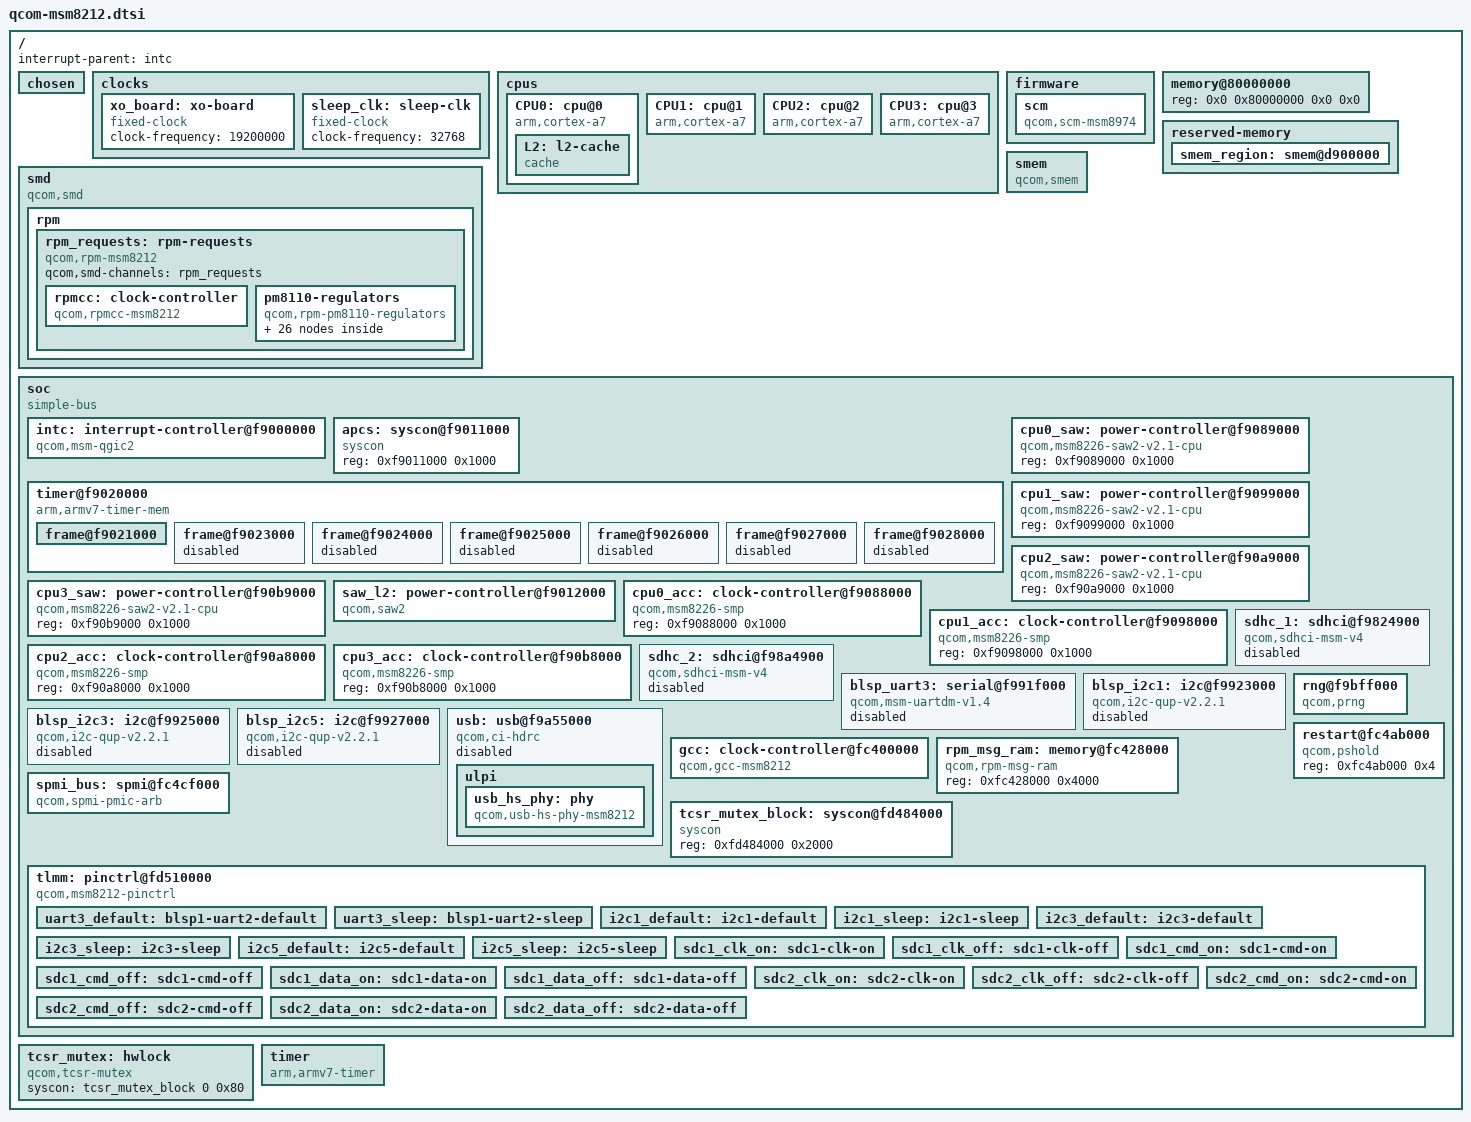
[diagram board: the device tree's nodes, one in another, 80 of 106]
// SPDX-License-Identifier: BSD-3-Clause
/*
 * Copyright (c) 2021, Konrad Dybcio
 * Copyright (c) 2021, Ivaylo Ivanov <ivo.ivanov@null.net>
 */

#include <dt-bindings/clock/qcom,gcc-msm8974.h>
#include <dt-bindings/clock/qcom,rpmcc.h>
#include <dt-bindings/gpio/gpio.h>
#include <dt-bindings/interrupt-controller/arm-gic.h>
#include <dt-bindings/reset/qcom,gcc-msm8974.h>

/ {
	interrupt-parent = <&intc>;

	#address-cells = <2>;
	#size-cells = <2>;

	chosen { };

	clocks {
		xo_board: xo-board {
			compatible = "fixed-clock";
			#clock-cells = <0>;
			clock-frequency = <19200000>;
		};

		sleep_clk: sleep-clk {
			compatible = "fixed-clock";
			#clock-cells = <0>;
			clock-frequency = <32768>;
		};
	};

	cpus {
		#address-cells = <1>;
		#size-cells = <0>;

		CPU0: cpu@0 {
			compatible = "arm,cortex-a7";
			enable-method = "qcom,msm8226-smp";
			device_type = "cpu";
			reg = <0>;
			next-level-cache = <&L2>;
			qcom,acc = <&cpu0_acc>;
			qcom,saw = <&cpu0_saw>;

			L2: l2-cache {
				compatible = "cache";
				cache-level = <2>;
				qcom,saw = <&saw_l2>;
			};
		};

		CPU1: cpu@1 {
			compatible = "arm,cortex-a7";
			enable-method = "qcom,msm8226-smp";
			device_type = "cpu";
			reg = <1>;
			next-level-cache = <&L2>;
			qcom,acc = <&cpu1_acc>;
			qcom,saw = <&cpu1_saw>;
		};

		CPU2: cpu@2 {
			compatible = "arm,cortex-a7";
			enable-method = "qcom,msm8226-smp";
			device_type = "cpu";
			reg = <2>;
			next-level-cache = <&L2>;
			qcom,acc = <&cpu2_acc>;
			qcom,saw = <&cpu2_saw>;
		};

		CPU3: cpu@3 {
			compatible = "arm,cortex-a7";
			enable-method = "qcom,msm8226-smp";
			device_type = "cpu";
			reg = <3>;
			next-level-cache = <&L2>;
			qcom,acc = <&cpu3_acc>;
			qcom,saw = <&cpu3_saw>;
		};
	};

	firmware {
		scm {
			compatible = "qcom,scm-msm8974", "qcom,scm";
			clocks = <&gcc GCC_CE1_CLK>,
				 <&gcc GCC_CE1_AXI_CLK>,
				 <&gcc GCC_CE1_AHB_CLK>;
			clock-names = "core", "bus", "iface";
		};
	};

	memory@80000000 {
		device_type = "memory";
		/* We expect the bootloader to fill in the reg */
		reg = <0x0 0x80000000 0x0 0x0>;
	};

	reserved-memory {
		#address-cells = <2>;
		#size-cells = <2>;
		ranges;

		smem_region: smem@d900000 {
			reg = <0 0xd900000 0 0x100000>;
			no-map;
		};
	};

	smd {
		compatible = "qcom,smd";

		rpm {
			interrupts = <GIC_SPI 168 IRQ_TYPE_EDGE_RISING>;
			qcom,ipc = <&apcs 8 0>;
			qcom,smd-edge = <15>;

			rpm_requests: rpm-requests {
				compatible = "qcom,rpm-msm8212";
				qcom,smd-channels = "rpm_requests";

				rpmcc: clock-controller {
					compatible = "qcom,rpmcc-msm8212", "qcom,rpmcc";
					#clock-cells = <1>;
				};

				pm8110-regulators {
					compatible = "qcom,rpm-pm8110-regulators";

					pm8110_s1: s1 {};
					pm8110_s2: s2 {};
					pm8110_s3: s3 {};
					pm8110_s4: s4 {};

					pm8110_l1: l1 {};
					pm8110_l2: l2 {};
					pm8110_l3: l3 {};
					pm8110_l4: l4 {};
					pm8110_l5: l5 {};
					pm8110_l6: l6 {};
					pm8110_l7: l7 {};
					pm8110_l8: l8 {};
					pm8110_l9: l9 {};
					pm8110_l10: l10 {};
					pm8110_l11: l11 {};
					pm8110_l12: l12 {};
					pm8110_l13: l13 {};
					pm8110_l14: l14 {};
					pm8110_l15: l15 {};
					pm8110_l16: l16 {};
					pm8110_l17: l17 {};
					pm8110_l18: l18 {};
					pm8110_l19: l19 {};
					pm8110_l20: l20 {};
					pm8110_l21: l21 {};
					pm8110_l22: l22 {};
				};
			};
		};
	};

	smem {
		compatible = "qcom,smem";

		memory-region = <&smem_region>;
		qcom,rpm-msg-ram = <&rpm_msg_ram>;

		hwlocks = <&tcsr_mutex 3>;
	};

	soc: soc {
		#address-cells = <1>;
		#size-cells = <1>;
		ranges = <0 0 0 0xffffffff>;
		compatible = "simple-bus";

		intc: interrupt-controller@f9000000 {
			compatible = "qcom,msm-qgic2";
			reg = <0xf9000000 0x1000>,
			      <0xf9002000 0x1000>;
			interrupt-controller;
			#interrupt-cells = <3>;
		};

		apcs: syscon@f9011000 {
			compatible = "syscon";
			reg = <0xf9011000 0x1000>;
		};

		timer@f9020000 {
			compatible = "arm,armv7-timer-mem";
			reg = <0xf9020000 0x1000>;
			clock-frequency = <19200000>;
			#address-cells = <1>;
			#size-cells = <1>;
			ranges;

			frame@f9021000 {
				frame-number = <0>;
				interrupts = <GIC_SPI 8 IRQ_TYPE_LEVEL_HIGH>,
					     <GIC_SPI 7 IRQ_TYPE_LEVEL_HIGH>;
				reg = <0xf9021000 0x1000>,
				      <0xf9022000 0x1000>;
			};

			frame@f9023000 {
				frame-number = <1>;
				interrupts = <GIC_SPI 9 IRQ_TYPE_LEVEL_HIGH>;
				reg = <0xf9023000 0x1000>;
				status = "disabled";
			};

			frame@f9024000 {
				frame-number = <2>;
				interrupts = <GIC_SPI 10 IRQ_TYPE_LEVEL_HIGH>;
				reg = <0xf9024000 0x1000>;
				status = "disabled";
			};

			frame@f9025000 {
				frame-number = <3>;
				interrupts = <GIC_SPI 11 IRQ_TYPE_LEVEL_HIGH>;
				reg = <0xf9025000 0x1000>;
				status = "disabled";
			};

			frame@f9026000 {
				frame-number = <4>;
				interrupts = <GIC_SPI 12 IRQ_TYPE_LEVEL_HIGH>;
				reg = <0xf9026000 0x1000>;
				status = "disabled";
			};

			frame@f9027000 {
				frame-number = <5>;
				interrupts = <GIC_SPI 13 IRQ_TYPE_LEVEL_HIGH>;
				reg = <0xf9027000 0x1000>;
				status = "disabled";
			};

			frame@f9028000 {
				frame-number = <6>;
				interrupts = <GIC_SPI 14 IRQ_TYPE_LEVEL_HIGH>;
				reg = <0xf9028000 0x1000>;
				status = "disabled";
			};
		};

		cpu0_saw: power-controller@f9089000 {
			compatible = "qcom,msm8226-saw2-v2.1-cpu", "qcom,saw2";
			reg = <0xf9089000 0x1000>;
		};

		cpu1_saw: power-controller@f9099000 {
			compatible = "qcom,msm8226-saw2-v2.1-cpu", "qcom,saw2";
			reg = <0xf9099000 0x1000>;
		};

		cpu2_saw: power-controller@f90a9000 {
			compatible = "qcom,msm8226-saw2-v2.1-cpu", "qcom,saw2";
			reg = <0xf90a9000 0x1000>;
		};

		cpu3_saw: power-controller@f90b9000 {
			compatible = "qcom,msm8226-saw2-v2.1-cpu", "qcom,saw2";
			reg = <0xf90b9000 0x1000>;
		};

		saw_l2: power-controller@f9012000 {
			compatible = "qcom,saw2";
			reg = <0xf9012000 0x1000>;
			regulator;
		};

		cpu0_acc: clock-controller@f9088000 {
			compatible = "qcom,msm8226-smp";
			reg = <0xf9088000 0x1000>;
		};

		cpu1_acc: clock-controller@f9098000 {
			compatible = "qcom,msm8226-smp";
			reg = <0xf9098000 0x1000>;
		};

		cpu2_acc: clock-controller@f90a8000 {
			compatible = "qcom,msm8226-smp";
			reg = <0xf90a8000 0x1000>;
		};

		cpu3_acc: clock-controller@f90b8000 {
			compatible = "qcom,msm8226-smp";
			reg = <0xf90b8000 0x1000>;
		};

		sdhc_1: sdhci@f9824900 {
			compatible = "qcom,sdhci-msm-v4";
			reg = <0xf9824900 0x11c>, <0xf9824000 0x800>;
			reg-names = "hc_mem", "core_mem";

			interrupts = <GIC_SPI 123 IRQ_TYPE_LEVEL_HIGH>,
				     <GIC_SPI 138 IRQ_TYPE_LEVEL_HIGH>;
			interrupt-names = "hc_irq", "pwr_irq";

			clocks = <&gcc GCC_SDCC1_APPS_CLK>,
				 <&gcc GCC_SDCC1_AHB_CLK>,
				 <&xo_board>;
			clock-names = "core", "iface", "xo";

			pinctrl-names = "default", "sleep";
			pinctrl-0 = <&sdc1_clk_on &sdc1_cmd_on &sdc1_data_on>;
			pinctrl-1 = <&sdc1_clk_off &sdc1_cmd_off &sdc1_data_off>;

			bus-width = <8>;
			non-removable;

			status = "disabled";
		};

		sdhc_2: sdhci@f98a4900 {
			compatible = "qcom,sdhci-msm-v4";
			reg = <0xf98a4900 0x11c>, <0xf98a4000 0x800>;
			reg-names = "hc_mem", "core_mem";

			interrupts = <GIC_SPI 125 IRQ_TYPE_LEVEL_HIGH>,
				     <GIC_SPI 221 IRQ_TYPE_LEVEL_HIGH>;
			interrupt-names = "hc_irq", "pwr_irq";

			clocks = <&gcc GCC_SDCC2_APPS_CLK>,
				 <&gcc GCC_SDCC2_AHB_CLK>,
				 <&xo_board>;
			clock-names = "core", "iface", "xo";

			pinctrl-names = "default", "sleep";
			pinctrl-0 = <&sdc2_clk_on &sdc2_cmd_on &sdc2_data_on>;
			pinctrl-1 = <&sdc2_clk_off &sdc2_cmd_off &sdc2_data_off>;

			bus-width = <8>;
			non-removable;

			status = "disabled";
		};

		blsp_uart3: serial@f991f000 {
			compatible = "qcom,msm-uartdm-v1.4", "qcom,msm-uartdm";
			reg = <0xf991f000 0x1000>;
			interrupts = <GIC_SPI 109 IRQ_TYPE_LEVEL_HIGH>;
			clock-names = "core", "iface";
			clocks = <&gcc GCC_BLSP1_UART3_APPS_CLK>,
				 <&gcc GCC_BLSP1_AHB_CLK>;
			pinctrl-names = "default", "sleep";
			pinctrl-0 = <&uart3_default>;
			pinctrl-1 = <&uart3_sleep>;
			status = "disabled";
		};

		blsp_i2c1: i2c@f9923000 {	
			compatible = "qcom,i2c-qup-v2.2.1";
			reg = <0xf9923000 0x1000>;
			interrupts = <GIC_SPI 95 IRQ_TYPE_LEVEL_HIGH>;

			clocks = <&gcc GCC_BLSP1_QUP1_I2C_APPS_CLK>,
				 <&gcc GCC_BLSP1_AHB_CLK>;
			clock-names = "core", "iface";
			clock-frequency = <400000>;

			pinctrl-names = "default", "sleep";
			pinctrl-0 = <&i2c1_default>;
			pinctrl-1 = <&i2c1_sleep>;
			#address-cells = <1>;
			#size-cells = <0>;
			status = "disabled";
		};

		/* I2C2 doesn't exist */

		blsp_i2c3: i2c@f9925000 {
			compatible = "qcom,i2c-qup-v2.2.1";
			reg = <0xf9925000 0x1000>;
			interrupts = <GIC_SPI 97 IRQ_TYPE_LEVEL_HIGH>;

			clocks = <&gcc GCC_BLSP1_QUP3_I2C_APPS_CLK>,
				 <&gcc GCC_BLSP1_AHB_CLK>;
			clock-names = "core", "iface";
			clock-frequency = <400000>;

			pinctrl-names = "default", "sleep";
			pinctrl-0 = <&i2c3_default>;
			pinctrl-1 = <&i2c3_sleep>;
			#address-cells = <1>;
			#size-cells = <0>;
			status = "disabled";
		};

		/* I2C4 doesn't exist */

		blsp_i2c5: i2c@f9927000 {
			compatible = "qcom,i2c-qup-v2.2.1";
			reg = <0xf9927000 0x1000>;
			interrupts = <GIC_SPI 101 IRQ_TYPE_LEVEL_HIGH>;

			clocks = <&gcc GCC_BLSP1_QUP5_I2C_APPS_CLK>,
				 <&gcc GCC_BLSP1_AHB_CLK>;
			clock-names = "core", "iface";
			clock-frequency = <400000>;

			pinctrl-names = "default", "sleep";
			pinctrl-0 = <&i2c5_default>;
			pinctrl-1 = <&i2c5_sleep>;
			#address-cells = <1>;
			#size-cells = <0>;
			status = "disabled";
		};

		usb: usb@f9a55000 {
			compatible = "qcom,ci-hdrc";
			reg = <0xf9a55000 0x200>,
			      <0xf9a55200 0x200>;
			interrupts = <GIC_SPI 134 IRQ_TYPE_LEVEL_HIGH>;
			clocks = <&gcc GCC_USB_HS_AHB_CLK>,
				 <&gcc GCC_USB_HS_SYSTEM_CLK>;
			clock-names = "iface", "core";
			assigned-clocks = <&gcc GCC_USB_HS_SYSTEM_CLK>;
			assigned-clock-rates = <75000000>;
			resets = <&gcc GCC_USB_HS_BCR>;
			reset-names = "core";
			phy_type = "ulpi";
			dr_mode = "otg";
			hnp-disable;
			srp-disable;
			adp-disable;
			ahb-burst-config = <0>;
			phy-names = "usb-phy";
			phys = <&usb_hs_phy>;
			status = "disabled";
			#reset-cells = <1>;

			ulpi {
				usb_hs_phy: phy {
					compatible = "qcom,usb-hs-phy-msm8212",
							"qcom,usb-hs-phy";
					#phy-cells = <0>;
					clocks = <&xo_board>,
						 <&gcc GCC_USB2A_PHY_SLEEP_CLK>;
					clock-names = "ref", "sleep";
					resets = <&gcc GCC_USB2A_PHY_BCR>,
						 <&usb 0>;
					reset-names = "phy", "por";
					qcom,init-seq = /bits/ 8 <0x0 0x44
						0x1 0x68 0x2 0x24 0x3 0x13>;
				};
			};
		};

		rng@f9bff000 {
			compatible = "qcom,prng";
			reg = <0xf9bff000 0x200>;
			clocks = <&gcc GCC_PRNG_AHB_CLK>;
			clock-names = "core";
		};

		gcc: clock-controller@fc400000 {
			compatible = "qcom,gcc-msm8212";
			#clock-cells = <1>;
			#reset-cells = <1>;
			#power-domain-cells = <1>;
			reg = <0xfc400000 0x2000>;

			clock-names = "xo", "sleep_clk";
			clocks = <&xo_board>,
				 <&sleep_clk>;
		};

		rpm_msg_ram: memory@fc428000 {
			compatible = "qcom,rpm-msg-ram";
			reg = <0xfc428000 0x4000>;
		};


		restart@fc4ab000 {
			compatible = "qcom,pshold";
			reg = <0xfc4ab000 0x4>;
		};

		spmi_bus: spmi@fc4cf000 {
			compatible = "qcom,spmi-pmic-arb";
			reg-names = "core", "intr", "cnfg";
			reg = <0xfc4cf000 0x1000>,
			      <0xfc4cb000 0x1000>,
			      <0xfc4ca000 0x1000>;
			interrupt-names = "periph_irq";
			interrupts = <GIC_SPI 190 IRQ_TYPE_LEVEL_HIGH>;
			qcom,ee = <0>;
			qcom,channel = <0>;
			#address-cells = <2>;
			#size-cells = <0>;
			interrupt-controller;
			#interrupt-cells = <4>;
		};

		tcsr_mutex_block: syscon@fd484000 {
			compatible = "syscon";
			reg = <0xfd484000 0x2000>;
		};

		tlmm: pinctrl@fd510000 {
			compatible = "qcom,msm8212-pinctrl";
			reg = <0xfd510000 0x4000>;
			interrupts = <GIC_SPI 208 IRQ_TYPE_LEVEL_HIGH>;
			gpio-controller;
			gpio-ranges = <&tlmm 0 0 102>;
			#gpio-cells = <2>;
			interrupt-controller;
			#interrupt-cells = <2>;

			uart3_default: blsp1-uart2-default {
				function = "blsp_uart3";
				pins = "gpio8", "gpio9";
				drive-strength = <16>;
				bias-disable;
			};

			uart3_sleep: blsp1-uart2-sleep {
				function = "gpio";
				pins = "gpio8", "gpio9";
				drive-strength = <2>;
				bias-pull-down;
			};

			i2c1_default: i2c1-default {
				pins = "gpio2", "gpio3";
				function = "blsp_i2c1";
				drive-strength = <2>;
				bias-disable;
			};

			i2c1_sleep: i2c1-sleep {
				pins = "gpio2", "gpio3";
				function = "blsp_i2c1";
				drive-strength = <2>;
				bias-pull-up;
			};

			i2c3_default: i2c3-default {
				pins = "gpio10", "gpio11";
				function = "blsp_i2c3";
				drive-strength = <2>;
				bias-disable;
			};

			i2c3_sleep: i2c3-sleep {
				pins = "gpio10", "gpio11";
				function = "blsp_i2c3";
				drive-strength = <2>;
				bias-pull-up;
			};

			i2c5_default: i2c5-default {
				pins = "gpio18", "gpio19";
				function = "blsp_i2c5";
				drive-strength = <2>;
				bias-disable;
			};

			i2c5_sleep: i2c5-sleep {
				pins = "gpio18", "gpio19";
				function = "blsp_i2c5";
				drive-strength = <2>;
				bias-pull-up;
			};

			sdc1_clk_on: sdc1-clk-on {
				pins = "sdc1_clk";
				bias-disable;
				drive-strength = <16>;
			};

			sdc1_clk_off: sdc1-clk-off {
				pins = "sdc1_clk";
				bias-disable;
				drive-strength = <2>;
			};

			sdc1_cmd_on: sdc1-cmd-on {
				pins = "sdc1_cmd";
				bias-pull-up;
				drive-strength = <10>;
			};

			sdc1_cmd_off: sdc1-cmd-off {
				pins = "sdc1_cmd";
				bias-pull-up;
				drive-strength = <2>;
			};

			sdc1_data_on: sdc1-data-on {
				pins = "sdc1_data";
				bias-pull-up;
				drive-strength = <8>;
			};

			sdc1_data_off: sdc1-data-off {
				pins = "sdc1_data";
				bias-pull-up;
				drive-strength = <2>;
			};

			sdc2_clk_on: sdc2-clk-on {
				pins = "sdc2_clk";
				bias-disable;
				drive-strength = <10>;
			};

			sdc2_clk_off: sdc2-clk-off {
				pins = "sdc2_clk";
				bias-disable;
				drive-strength = <2>;
			};

			sdc2_cmd_on: sdc2-cmd-on {
				pins = "sdc2_cmd";
				bias-pull-up;
				drive-strength = <10>;
			};

			sdc2_cmd_off: sdc2-cmd-off {
				pins = "sdc2_cmd";
				bias-pull-up;
				drive-strength = <2>;
			};

			sdc2_data_on: sdc2-data-on {
				pins = "sdc2_data";
				bias-pull-up;
				drive-strength = <10>;
			};

			sdc2_data_off: sdc2-data-off {
				pins = "sdc2_data";
				bias-pull-up;
				drive-strength = <2>;
			};
		};
	};

	tcsr_mutex: hwlock {
		compatible = "qcom,tcsr-mutex";
		syscon = <&tcsr_mutex_block 0 0x80>;

		#hwlock-cells = <1>;
	};

	timer {
		compatible = "arm,armv7-timer";
		interrupts = <GIC_PPI 2
				(GIC_CPU_MASK_RAW(15) | IRQ_TYPE_LEVEL_LOW)>,
			     <GIC_PPI 3
				(GIC_CPU_MASK_RAW(15) | IRQ_TYPE_LEVEL_LOW)>,
			     <GIC_PPI 4
				(GIC_CPU_MASK_RAW(15) | IRQ_TYPE_LEVEL_LOW)>,
			     <GIC_PPI 1
				(GIC_CPU_MASK_RAW(15) | IRQ_TYPE_LEVEL_LOW)>;
	};
};
